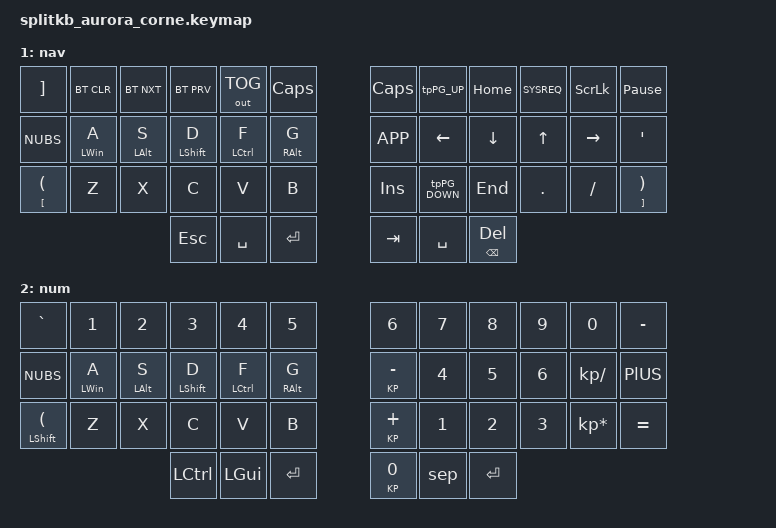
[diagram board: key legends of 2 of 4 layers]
/*
 * Copyright (c) 2020 The ZMK Contributors
 *
 * SPDX-License-Identifier: MIT
 */

#include <behaviors.dtsi>
#include <dt-bindings/zmk/keys.h>
#include <dt-bindings/zmk/bt.h>
#include <dt-bindings/zmk/outputs.h>

/* Layers */
#define BASE 0
#define NAV 1
#define NUM 3
#define NUMP 4
/ {
    behaviors {
        tldesc: tilde_escape {
            compatible = "zmk,behavior-mod-morph";
            label = "TILDE_ESCAPE";
            #binding-cells = <0>;
            bindings = <&kp ESC>, <&kp TILDE>;
            mods = <(MOD_LSFT|MOD_RSFT)>;
        };

        bspc_del: backspace_delete {
            compatible = "zmk,behavior-mod-morph";
            label = "BACKSPACE_DELETE";
            #binding-cells = <0>;
            bindings = <&kp BACKSPACE>, <&kp DELETE>;
            mods = <(MOD_LSFT|MOD_RSFT)>;
            keep-mods = <(MOD_RSFT)>;
        };
        td_comma: tap_dance_comma {
            compatible = "zmk,behavior-tap-dance";
            label = "TAP_DANCE_COMMA";
            #binding-cells = <0>;
            tapping-term-ms = <200>;
            bindings = <&kp COMMA>, <&kp RA(EQUAL)>;
        };
        td_dot: tap_dance_dot {
            compatible = "zmk,behavior-tap-dance";
            label = "TAP_DANCE_DOT";
            #binding-cells = <0>;
            tapping-term-ms = <200>;
            bindings = <&kp DOT>, <&kp RS(7)>;
        };
        td_fslh: tap_dance_fslh {
            compatible = "zmk,behavior-tap-dance";
            label = "TAP_DANCE_FSLH";
            #binding-cells = <0>;
            tapping-term-ms = <200>;
            bindings = <&kp FSLH>, <&kp RS(EQUAL)>;
        };
        td_pgup: tap_dance_pgup {
            compatible = "zmk,behavior-tap-dance";
            label = "TAP_DANCE_PGUP";
            #binding-cells = <0>;
            tapping-term-ms = <200>;
            bindings = <&kp PGUP>, <&kp LC(PGUP)>;
        };
        td_pgup: tap_dance_pgdn {
            compatible = "zmk,behavior-tap-dance";
            label = "TAP_DANCE_PGDN";
            #binding-cells = <0>;
            tapping-term-ms = <200>;
            bindings = <&kp PGDN>, <&kp LC(PGDN)>;
        };
        hr: left_hand_positional_hold_tap {
            compatible = "zmk,behavior-hold-tap";
            label = "LEFT_POSITIONAL_HOLD_TAP";
            #binding-cells = <2>;
            flavor = "tap-unless-interrupted";
            tapping-term-ms = <100>;                        // <---[[produces tap if held longer than tapping-term-ms]]
            quick-tap-ms = <200>;
            bindings = <&kp>, <&kp>;
            hold-trigger-key-positions = <5 6 7 8 9 10>;    // <---[[right-hand keys]]
        };
};

  keymap {
    compatible = "zmk,keymap";
    base_layer {
      label = "base";
      bindings = <
        // ╭──────────────────┬──────────┬──────────┬─────────────┬────────────┬─────────────╮   ╭─────────────┬─────────────┬──────────────┬───────────┬────────────┬──────────────────╮
              &kp RBKT          &kp Q     &kp W       &kp E        &kp R        &kp T              &kp Y                   &kp U                    &kp I                     &kp O                &kp P                 &kp LBKT
        // ├──────────────────┼──────────┼──────────┼─────────────┼────────────┼─────────────┤   ├─────────────┼─────────────┼──────────────┼───────────┼────────────┼──────────────────┤
              &kp NUBS        &ht_tp LWIN A &ht_tp LALT S &ht_tp LSHFT D &ht_tp LCTRL F          &ht_tp RALT G                  &ht_tp RALT H              &ht_tp RCTRL  J             &ht_tp LALT K                &ht_tp RSHFT L          &ht_tp RWIN SEMI         &kp SQT
        // ├──────────────────┼──────────┼──────────┼─────────────┼────────────┼─────────────┤   ├─────────────┼─────────────┼──────────────┼───────────┼────────────┼──────────────────┤
              &mt LBKT LPAR     &kp Z      &kp X      &kp C         &kp V       &kp B                       &kp N                   &kp M                    &tp_comma                 &tp_dot              &tp_fslh              &mt RBKT RPAR
        // ╰──────────────────┴──────────┴──────────┴─────────────┼────────────┼─────────────┤   ├─────────────┼─────────────┼──────────────┴───────────┴────────────┴──────────────────╯
                                                                                &ltu NUMP ESCAPE           &ht_tp LSHFT SPACE           &lt NAV RET                 &lt NAV TAB           &ht_tp LSHFT SPACE         &lt NUM &mt BKSP DEL
        //                                                                        ╰─────────────┴────────────┴─────────────╯     ╰─────────────┴─────────────┴──────────────╯
      >;
    };
    nav_layer {
      label = "nav";
      bindings = <
        // ╭──────────────────┬──────────┬──────────┬─────────────┬────────────┬─────────────╮   ╭─────────────┬─────────────┬──────────────┬───────────┬────────────┬──────────────────╮
              &kp RBKT         &bt BT_CLR &bt BT_NXT  &bt BT_PRV   &out OUT_TOG  &kp CAPS          &kp CAPS              &tpPG_UP               &kp HOME               &kp SYSREQ         &kp SLCK             &kp PAUSE_BREAK
        // ├──────────────────┼──────────┼──────────┼─────────────┼────────────┼─────────────┤   ├─────────────┼─────────────┼──────────────┼───────────┼────────────┼──────────────────┤
              &kp NUBS                      &ht_tp LWIN A        &ht_tp LALT S       &ht_tp LSHIFT D           &ht_tp LCTRL F         &ht_tp RALT G                  &kp K_APP             &kp LEFT               &kp DOWN               &kp UP             &kp RIGHT            &kp SQT
        // ├──────────────────┼──────────┼──────────┼─────────────┼────────────┼─────────────┤   ├─────────────┼─────────────┼──────────────┼───────────┼────────────┼──────────────────┤
              &mt LBKT LPAR                &kp Z              &kp X            &kp C                  &kp V               &kp B                       &kp INSERT            &tpPG_DOWN             &kp END                &kp DOT            &kp FSLH             &mt RBKT RPAR
        // ╰──────────────────┴──────────┴──────────┴─────────────┼────────────┼─────────────┤   ├─────────────┼─────────────┼──────────────┴───────────┴────────────┴──────────────────╯
                                                                                &kp ESCAPE            &kp SPACE            &kp RET                   &kp TAB                &kp SPACE              &mt BKSP DEL
        //                                                                   ╰─────────────┴────────────┴─────────────╯   ╰─────────────┴─────────────┴──────────────╯
      >;
    };
  num_layer {
      label = "num";
      bindings = <
        // ╭──────────────────┬──────────┬──────────┬─────────────┬────────────┬─────────────╮   ╭─────────────┬─────────────┬──────────────┬───────────┬────────────┬──────────────────╮
              &kp GRAVE         &kp N1     &kp N2    &kp N3        &kp N4       &kp N5             &kp N6       &kp N7        &kp N8        &kp N9       &kp N0       &kp MINUS
        // ├──────────────────┼──────────┼──────────┼─────────────┼────────────┼─────────────┤   ├─────────────┼─────────────┼──────────────┼───────────┼────────────┼──────────────────┤
              &kp NUBS                      &ht_tp LWIN A        &ht_tp LALT S       &ht_tp LSHIFT D           &ht_tp LCTRL F         &ht_tp RALT G                 &KP MINUS              &kp N4                 &kp N5                  &kp N6             &kp KP_DIVIDE        &kp PlUS
        // ├──────────────────┼──────────┼──────────┼─────────────┼────────────┼─────────────┤   ├─────────────┼─────────────┼──────────────┼───────────┼────────────┼──────────────────┤
              &mt LSHFT LPAR                &kp Z             &kp X            &kp C                  &kp V               &kp B                      &KP PLUS               &kp N1                 &kp N2                  &kp N3             &kp KP_MULTIPLY      &kp EQUAL
        // ╰──────────────────┴──────────┴──────────┴─────────────┼────────────┼─────────────┤   ├─────────────┼─────────────┼──────────────┴───────────┴────────────┴──────────────────╯
                                                                                &kp LCTRL            &kp LGUI             &kp RET                    &KP N0                 &kp sep               &kp RETURN
        //                                                                   ╰─────────────┴────────────┴─────────────╯   ╰─────────────┴─────────────┴──────────────╯
      >;
    };
  nump_layer {
      label = "nump";
      bindings = <
        // ╭──────────────────┬──────────┬──────────┬─────────────┬────────────┬─────────────╮   ╭─────────────┬─────────────┬──────────────┬───────────┬────────────┬──────────────────╮
              &kp GRAVE                     &kp N1            &kp N2           &kp N3                 &kp N4              &kp N5                     &kp NUML               &kp KP N7            &kp KP N8               &kp KP N9          &kp KP N0            &kp MIKP NUS
        // ├──────────────────┼──────────┼──────────┼─────────────┼────────────┼─────────────┤   ├─────────────┼─────────────┼──────────────┼───────────┼────────────┼──────────────────┤
              &kp KP NUBS                   &kp A             &kp S            &kp D                  &kp F               &kp G                      &KP MIKP NUS           &kp KP N4             &ht_tp LCTRL KP N5         &kp KP N6          &kp KP DIVIDE        &kp PlUS
        // ├──────────────────┼──────────┼──────────┼─────────────┼────────────┼─────────────┤   ├─────────────┼─────────────┼──────────────┼───────────┼────────────┼──────────────────┤
              &mt LSHFT LPAR                &kp Z             &kp X            &kp C                  &kp V               &kp B                      &KP PLUS               &kp KP N1             &kp KP N2               &kp KP N3          &kp KP MULTIPLY      &kp EQUAL
        // ╰──────────────────┴──────────┴──────────┴─────────────┼────────────┼─────────────┤   ├─────────────┼─────────────┼──────────────┴───────────┴────────────┴──────────────────╯
                                                                                &kp LCTRL            &kp LGUI             &kp RET                    &KP KP N0                 &kp sep               &kp RETURKP N
        //                                                                   ╰─────────────┴────────────┴─────────────╯   ╰─────────────┴─────────────┴──────────────╯
      >;
    };
};
